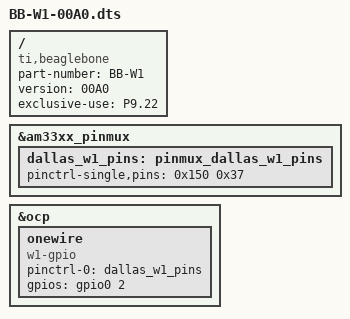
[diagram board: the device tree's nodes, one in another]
/*compile:

    $ dtc -O dtb -o BB-W1-00B0.dtbo -b o -@ BB-W1-00B0.dts

NOTE: on arch linux be sure to install dtc-overlay:

    # pacman -S dtc-overlay
*/

/dts-v1/;
/plugin/;
/ {
        compatible = "ti,beaglebone", "ti,beaglebone-black";
        part-number = "BB-W1";
        version = "00A0";
        
        exclusive-use = "P9.22";
        
        fragment@0 {
                target = <&am33xx_pinmux>;
                __overlay__ {
                        dallas_w1_pins: pinmux_dallas_w1_pins {
                                pinctrl-single,pins = < 0x150 0x37 >;
                        };
                };
        };
        
        fragment@1 {
                target = <&ocp>;
                __overlay__ {
                        #address-cells = ;
                        #size-cells = ;
                        onewire {
                                compatible      = "w1-gpio";
                                pinctrl-names   = "default";
                                pinctrl-0       = <&dallas_w1_pins>;
                                status          = "okay";
                                gpios           = <&gpio0 2 0>;
                        };
                };
        };
};
